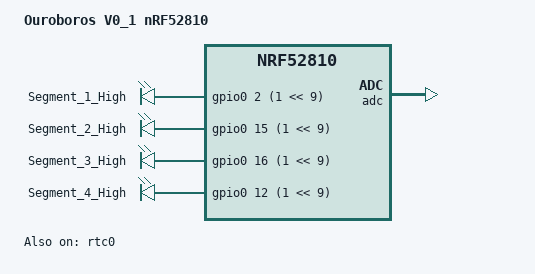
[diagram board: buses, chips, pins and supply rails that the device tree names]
// Copyright (c) 2024 Nordic Semiconductor ASA
// SPDX-License-Identifier: Apache-2.0

/dts-v1/;
#include <nordic/nrf52810_qfaa.dtsi>

/ {
	model = "Ouroboros V0_1 nRF52810";
	compatible = "jacob-lundstrom,ouroboros-v0-1-nrf52810";

	chosen {
		zephyr,sram = &sram0;
		zephyr,flash = &flash0;
		zephyr,code-partition = &slot0_partition;
	};

	aliases {
		led0 = &segment1high;
	};

	leds {
		compatible = "gpio-leds";

		segment1high: segment_1_high {
			gpios = <&gpio0 2 (1 << 9)>;
			label = "Segment_1_High";
		};

		segment2high: segment_2_high {
			gpios = <&gpio0 15 (1 << 9)>;
			label = "Segment_2_High";
		};

		segment3high: segment_3_high {
			gpios = <&gpio0 16 (1 << 9)>;
			label = "Segment_3_High";
		};

		segment4high: segment_4_high {
			gpios = <&gpio0 12 (1 << 9)>;
			label = "Segment_4_High";
		};

		
	};
};

&flash0 {
	partitions {
		compatible = "fixed-partitions";
		#address-cells = <1>;
		#size-cells = <1>;

		boot_partition: partition@0 {
			label = "mcuboot";
			reg = <0x0 0xc000>;
		};
		slot0_partition: partition@c000 {
			label = "image-0";
			reg = <0xc000 0xa000>;
		};
		slot1_partition: partition@16000 {
			label = "image-1";
			reg = <0x16000 0xa000>;
		};
		scratch_partition: partition@20000 {
			label = "image-scratch";
			reg = <0x20000 0xa000>;
		};
		storage_partition: partition@2a000 {
			label = "storage";
			reg = <0x2a000 0x6000>;
		};
	};
};





&gpio0 {
	status = "okay";
	gpiote-instance = <&gpiote>;
};

&gpiote {
	status = "okay";
};

&rtc0 {
	status = "okay";
	clock-frequency = <32768>;
};

&power {
	status = "disabled";
};

&adc {
	status = "okay";
};
